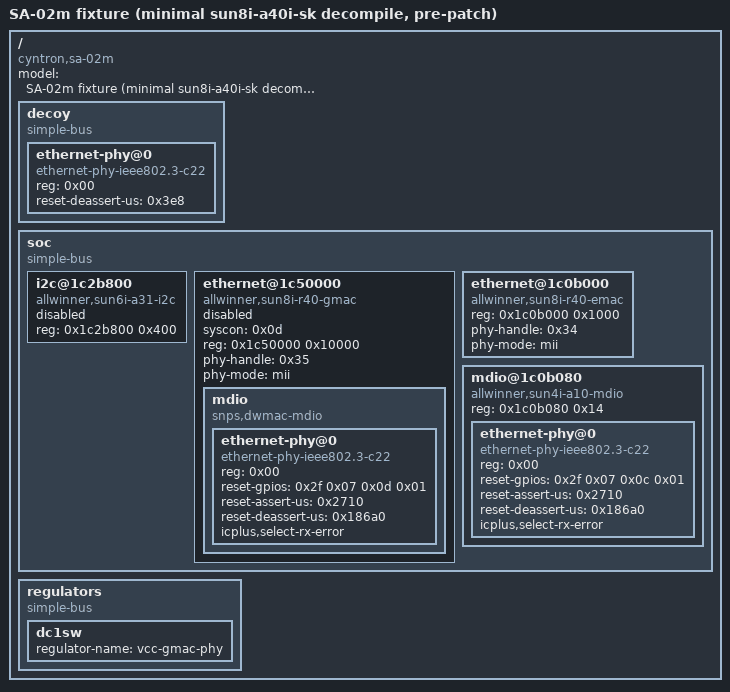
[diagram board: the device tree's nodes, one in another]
/dts-v1/;

/ {
	#address-cells = <0x01>;
	#size-cells = <0x01>;
	model = "SA-02m fixture (minimal sun8i-a40i-sk decompile, pre-patch)";
	compatible = "cyntron,sa-02m", "allwinner,sun8i-r40";

	decoy {
		compatible = "simple-bus";

		ethernet-phy@0 {
			compatible = "ethernet-phy-ieee802.3-c22";
			reg = <0x00>;
			reset-deassert-us = <0x3e8>;
		};
	};

	soc {
		compatible = "simple-bus";
		#address-cells = <0x01>;
		#size-cells = <0x01>;
		ranges;

		i2c@1c2b800 {
			compatible = "allwinner,sun6i-a31-i2c";
			reg = <0x1c2b800 0x400>;
			status = "disabled";
			phandle = <0x30>;
		};

		ethernet@1c50000 {
			compatible = "allwinner,sun8i-r40-gmac";
			syscon = <0x0d>;
			reg = <0x1c50000 0x10000>;
			phy-handle = <0x35>;
			phy-mode = "mii";
			status = "disabled";

			mdio {
				compatible = "snps,dwmac-mdio";
				#address-cells = <0x01>;
				#size-cells = <0x00>;

				ethernet-phy@0 {
					compatible = "ethernet-phy-ieee802.3-c22";
					reg = <0x00>;
					reset-gpios = <0x2f 0x07 0x0d 0x01>;
					reset-assert-us = <0x2710>;
					reset-deassert-us = <0x186a0>;
					icplus,select-rx-error;
					phandle = <0x35>;
				};
			};
		};

		ethernet@1c0b000 {
			compatible = "allwinner,sun8i-r40-emac";
			reg = <0x1c0b000 0x1000>;
			phy-handle = <0x34>;
			phy-mode = "mii";
			status = "okay";
		};

		mdio@1c0b080 {
			compatible = "allwinner,sun4i-a10-mdio";
			reg = <0x1c0b080 0x14>;
			#address-cells = <0x01>;
			#size-cells = <0x00>;
			status = "okay";

			ethernet-phy@0 {
				compatible = "ethernet-phy-ieee802.3-c22";
				reg = <0x00>;
				reset-gpios = <0x2f 0x07 0x0c 0x01>;
				reset-assert-us = <0x2710>;
				reset-deassert-us = <0x186a0>;
				icplus,select-rx-error;
				phandle = <0x34>;
			};
		};
	};

	regulators {
		compatible = "simple-bus";

		dc1sw {
			regulator-name = "vcc-gmac-phy";
			phandle = <0x36>;
		};
	};
};
